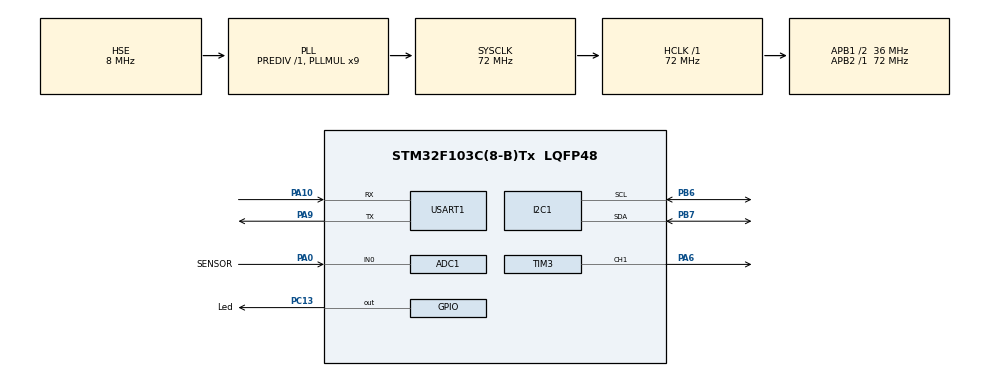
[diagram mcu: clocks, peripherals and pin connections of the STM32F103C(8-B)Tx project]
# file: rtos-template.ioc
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ADC1.Channel-0\#ChannelRegularConversion=ADC_CHANNEL_0
ADC1.ContinuousConvMode=DISABLE
ADC1.DataAlign=ADC_DATAALIGN_RIGHT
ADC1.DiscontinuousConvMode=DISABLE
ADC1.EnableAnalogWatchDog=false
ADC1.EnableRegularConversion=ENABLE
ADC1.ExternalTrigConv=ADC_EXTERNALTRIGCONV_T3_TRGO
ADC1.InjNumberOfConversion=0
ADC1.NbrOfConversion=1
ADC1.NbrOfConversionFlag=1
ADC1.Rank-0\#ChannelRegularConversion=1
ADC1.SamplingTime-0\#ChannelRegularConversion=ADC_SAMPLETIME_1CYCLE_5
ADC1.ScanConvMode=ADC_SCAN_DISABLE
ADC1.master=1
Dma.ADC1.0.Direction=DMA_PERIPH_TO_MEMORY
Dma.ADC1.0.Instance=DMA1_Channel1
Dma.ADC1.0.MemDataAlignment=DMA_MDATAALIGN_HALFWORD
Dma.ADC1.0.MemInc=DMA_MINC_ENABLE
Dma.ADC1.0.Mode=DMA_CIRCULAR
Dma.ADC1.0.PeriphDataAlignment=DMA_PDATAALIGN_HALFWORD
Dma.ADC1.0.PeriphInc=DMA_PINC_DISABLE
Dma.ADC1.0.Priority=DMA_PRIORITY_LOW
Dma.Request0=ADC1
FREERTOS.Tasks01=defaultTask,0,128,StartDefaultTask,Default,NULL
FREERTOS.configTOTAL_HEAP_SIZE=10000
Mcu.Family=STM32F1
Mcu.Name=STM32F103C(8-B)Tx
Mcu.Package=LQFP48
NVIC.DMA1_Channel1_IRQn=true\:5\:0\:false\:false\:true\:true\:false
NVIC.PriorityGroup=NVIC_PRIORITYGROUP_4
NVIC.TIM1_UP_IRQn=true\:0\:0\:false\:false\:true\:false\:false
NVIC.TimeBase=TIM1_UP_IRQn
NVIC.TimeBaseIP=TIM1
PA0-WKUP.GPIO_Label=SENSOR
PA0-WKUP.Signal=ADCx_IN0
PA10.Mode=Asynchronous
PA10.Signal=USART1_RX
PA6.Signal=S_TIM3_CH1
PA9.Mode=Asynchronous
PA9.Signal=USART1_TX
PB6.Mode=I2C
PB6.Signal=I2C1_SCL
PB7.Mode=I2C
PB7.Signal=I2C1_SDA
PC13-TAMPER-RTC.GPIO_Label=Led
PC13-TAMPER-RTC.Signal=GPIO_Output
PD0-OSC_IN.Mode=HSE-External-Oscillator
PD0-OSC_IN.Signal=RCC_OSC_IN
PD1-OSC_OUT.Mode=HSE-External-Oscillator
PD1-OSC_OUT.Signal=RCC_OSC_OUT
ProjectManager.HeapSize=0x200
ProjectManager.StackSize=0x400
ProjectManager.TargetToolchain=Other Toolchains (GPDSC)
RCC.ADCPresc=RCC_ADCPCLK2_DIV6
RCC.AHBFreq_Value=72000000
RCC.APB1CLKDivider=RCC_HCLK_DIV2
RCC.APB1Freq_Value=36000000
RCC.APB1TimFreq_Value=72000000
RCC.APB2Freq_Value=72000000
RCC.APB2TimFreq_Value=72000000
RCC.HCLKFreq_Value=72000000
RCC.PLLMUL=RCC_PLL_MUL9
RCC.PLLSourceVirtual=RCC_PLLSOURCE_HSE
RCC.SYSCLKFreq_VALUE=72000000
RCC.SYSCLKSource=RCC_SYSCLKSOURCE_PLLCLK
RCC.USBFreq_Value=72000000
SH.ADCx_IN0.0=ADC1_IN0,IN0
SH.S_TIM3_CH1.0=TIM3_CH1,Output Compare1 CH1
TIM3.AutoReloadPreload=TIM_AUTORELOAD_PRELOAD_ENABLE
TIM3.Channel-Output\ Compare1\ CH1=TIM_CHANNEL_1
TIM3.Period=56250-1
TIM3.Prescaler=10-1
TIM3.TIM_MasterOutputTrigger=TIM_TRGO_UPDATE
USART1.VirtualMode=VM_ASYNC
VP_FREERTOS_VS_ENABLE.Mode=Enabled
VP_SYS_VS_ND.Mode=No_Debug
VP_SYS_VS_tim1.Mode=TIM1
VP_TIM3_VS_ClockSourceINT.Mode=Internal
board=custom

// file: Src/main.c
/**
  ******************************************************************************
  * @file           : main.c
  * @brief          : Main program body
  ******************************************************************************
  * This notice applies to any and all portions of this file
  * that are not between comment pairs USER CODE BEGIN and
  * USER CODE END. Other portions of this file, whether
  * inserted by the user or by software development tools
  * are owned by their respective copyright owners.
  *
  * Copyright (c) 2020 STMicroelectronics International N.V.
  * All rights reserved.
  *
  * Redistribution and use in source and binary forms, with or without
  * modification, are permitted, provided that the following conditions are met:
  *
  * 1. Redistribution of source code must retain the above copyright notice,
  *    this list of conditions and the following disclaimer.
  * 2. Redistributions in binary form must reproduce the above copyright notice,
  *    this list of conditions and the following disclaimer in the documentation
  *    and/or other materials provided with the distribution.
  * 3. Neither the name of STMicroelectronics nor the names of other
  *    contributors to this software may be used to endorse or promote products
  *    derived from this software without specific written permission.
  * 4. This software, including modifications and/or derivative works of this
  *    software, must execute solely and exclusively on microcontroller or
  *    microprocessor devices manufactured by or for STMicroelectronics.
  * 5. Redistribution and use of this software other than as permitted under
  *    this license is void and will automatically terminate your rights under
  *    this license.
  *
  * THIS SOFTWARE IS PROVIDED BY STMICROELECTRONICS AND CONTRIBUTORS "AS IS"
  * AND ANY EXPRESS, IMPLIED OR STATUTORY WARRANTIES, INCLUDING, BUT NOT
  * LIMITED TO, THE IMPLIED WARRANTIES OF MERCHANTABILITY, FITNESS FOR A
  * PARTICULAR PURPOSE AND NON-INFRINGEMENT OF THIRD PARTY INTELLECTUAL PROPERTY
  * RIGHTS ARE DISCLAIMED TO THE FULLEST EXTENT PERMITTED BY LAW. IN NO EVENT
  * SHALL STMICROELECTRONICS OR CONTRIBUTORS BE LIABLE FOR ANY DIRECT, INDIRECT,
  * INCIDENTAL, SPECIAL, EXEMPLARY, OR CONSEQUENTIAL DAMAGES (INCLUDING, BUT NOT
  * LIMITED TO, PROCUREMENT OF SUBSTITUTE GOODS OR SERVICES; LOSS OF USE, DATA,
  * OR PROFITS; OR BUSINESS INTERRUPTION) HOWEVER CAUSED AND ON ANY THEORY OF
  * LIABILITY, WHETHER IN CONTRACT, STRICT LIABILITY, OR TORT (INCLUDING
  * NEGLIGENCE OR OTHERWISE) ARISING IN ANY WAY OUT OF THE USE OF THIS SOFTWARE,
  * EVEN IF ADVISED OF THE POSSIBILITY OF SUCH DAMAGE.
  *
  ******************************************************************************
  */
#include "main.h"
#include "stm32f1xx_hal.h"
#include "cmsis_os.h"
#include "adc.h"
#include "dma.h"
#include "i2c.h"
#include "tim.h"
#include "usart.h"
#include "gpio.h"

/* USER CODE BEGIN PV */
/* Private variables ---------------------------------------------------------*/

/* USER CODE END PV */

void SystemClock_Config(void);
void MX_FREERTOS_Init(void);

/* USER CODE BEGIN PFP */
/* Private function prototypes -----------------------------------------------*/

/* USER CODE END PFP */

int main(void)
{

  /* MCU Configuration----------------------------------------------------------*/

  /* Reset of all peripherals, Initializes the Flash interface and the Systick. */
  HAL_Init();

  /* Configure the system clock */
  SystemClock_Config();

  /* Initialize all configured peripherals */
  MX_GPIO_Init();
  MX_DMA_Init();
  MX_I2C1_Init();
  MX_USART1_UART_Init();
  MX_ADC1_Init();
  MX_TIM3_Init();

  /* Call init function for freertos objects (in freertos.c) */
  MX_FREERTOS_Init();

  /* Start scheduler */
  osKernelStart();

  /* We should never get here as control is now taken by the scheduler */

  /* Infinite loop */
  /* USER CODE BEGIN WHILE */
  while (1)
  {
    // HAL_GPIO_TogglePin(Led_GPIO_Port,Led_Pin);
    // HAL_Delay(100);
  /* USER CODE END WHILE */

  }

}

void SystemClock_Config(void)
{

  RCC_OscInitTypeDef RCC_OscInitStruct;
  RCC_ClkInitTypeDef RCC_ClkInitStruct;
  RCC_PeriphCLKInitTypeDef PeriphClkInit;

    /**Initializes the CPU, AHB and APB busses clocks
    */
  RCC_OscInitStruct.OscillatorType = RCC_OSCILLATORTYPE_HSE;
  RCC_OscInitStruct.HSEState = RCC_HSE_ON;
  RCC_OscInitStruct.HSEPredivValue = RCC_HSE_PREDIV_DIV1;
  RCC_OscInitStruct.HSIState = RCC_HSI_ON;
  RCC_OscInitStruct.PLL.PLLState = RCC_PLL_ON;
  RCC_OscInitStruct.PLL.PLLSource = RCC_PLLSOURCE_HSE;
  RCC_OscInitStruct.PLL.PLLMUL = RCC_PLL_MUL9;
  if (HAL_RCC_OscConfig(&RCC_OscInitStruct) != HAL_OK)
  {
    _Error_Handler(__FILE__, __LINE__);
  }

    /**Initializes the CPU, AHB and APB busses clocks
    */
  RCC_ClkInitStruct.ClockType = RCC_CLOCKTYPE_HCLK|RCC_CLOCKTYPE_SYSCLK
                              |RCC_CLOCKTYPE_PCLK1|RCC_CLOCKTYPE_PCLK2;
  RCC_ClkInitStruct.SYSCLKSource = RCC_SYSCLKSOURCE_PLLCLK;
  RCC_ClkInitStruct.AHBCLKDivider = RCC_SYSCLK_DIV1;
  RCC_ClkInitStruct.APB1CLKDivider = RCC_HCLK_DIV2;
  RCC_ClkInitStruct.APB2CLKDivider = RCC_HCLK_DIV1;

  if (HAL_RCC_ClockConfig(&RCC_ClkInitStruct, FLASH_LATENCY_2) != HAL_OK)
  {
    _Error_Handler(__FILE__, __LINE__);
  }

  PeriphClkInit.PeriphClockSelection = RCC_PERIPHCLK_ADC;
  PeriphClkInit.AdcClockSelection = RCC_ADCPCLK2_DIV6;
  if (HAL_RCCEx_PeriphCLKConfig(&PeriphClkInit) != HAL_OK)
  {
    _Error_Handler(__FILE__, __LINE__);
  }

    /**Configure the Systick interrupt time
    */
  HAL_SYSTICK_Config(HAL_RCC_GetHCLKFreq()/1000);

    /**Configure the Systick
    */
  HAL_SYSTICK_CLKSourceConfig(SYSTICK_CLKSOURCE_HCLK);

  /* SysTick_IRQn interrupt configuration */
  HAL_NVIC_SetPriority(SysTick_IRQn, 15, 0);
}

void HAL_TIM_PeriodElapsedCallback(TIM_HandleTypeDef *htim)
{
  if (htim->Instance == TIM1) {
    HAL_IncTick();
  }
}

void _Error_Handler(char *file, int line)
{
  while(1)
  {
  }
}

/************************ (C) COPYRIGHT STMicroelectronics *****END OF FILE****/

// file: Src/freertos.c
/* USER CODE BEGIN Header */
/**
  ******************************************************************************
  * File Name          : freertos.c
  * Description        : Code for freertos applications
  ******************************************************************************
  * This notice applies to any and all portions of this file
  * that are not between comment pairs USER CODE BEGIN and
  * USER CODE END. Other portions of this file, whether
  * inserted by the user or by software development tools
  * are owned by their respective copyright owners.
  *
  * Copyright (c) 2020 STMicroelectronics International N.V.
  * All rights reserved.
  *
  * Redistribution and use in source and binary forms, with or without
  * modification, are permitted, provided that the following conditions are met:
  *
  * 1. Redistribution of source code must retain the above copyright notice,
  *    this list of conditions and the following disclaimer.
  * 2. Redistributions in binary form must reproduce the above copyright notice,
  *    this list of conditions and the following disclaimer in the documentation
  *    and/or other materials provided with the distribution.
  * 3. Neither the name of STMicroelectronics nor the names of other
  *    contributors to this software may be used to endorse or promote products
  *    derived from this software without specific written permission.
  * 4. This software, including modifications and/or derivative works of this
  *    software, must execute solely and exclusively on microcontroller or
  *    microprocessor devices manufactured by or for STMicroelectronics.
  * 5. Redistribution and use of this software other than as permitted under
  *    this license is void and will automatically terminate your rights under
  *    this license.
  *
  * THIS SOFTWARE IS PROVIDED BY STMICROELECTRONICS AND CONTRIBUTORS "AS IS"
  * AND ANY EXPRESS, IMPLIED OR STATUTORY WARRANTIES, INCLUDING, BUT NOT
  * LIMITED TO, THE IMPLIED WARRANTIES OF MERCHANTABILITY, FITNESS FOR A
  * PARTICULAR PURPOSE AND NON-INFRINGEMENT OF THIRD PARTY INTELLECTUAL PROPERTY
  * RIGHTS ARE DISCLAIMED TO THE FULLEST EXTENT PERMITTED BY LAW. IN NO EVENT
  * SHALL STMICROELECTRONICS OR CONTRIBUTORS BE LIABLE FOR ANY DIRECT, INDIRECT,
  * INCIDENTAL, SPECIAL, EXEMPLARY, OR CONSEQUENTIAL DAMAGES (INCLUDING, BUT NOT
  * LIMITED TO, PROCUREMENT OF SUBSTITUTE GOODS OR SERVICES; LOSS OF USE, DATA,
  * OR PROFITS; OR BUSINESS INTERRUPTION) HOWEVER CAUSED AND ON ANY THEORY OF
  * LIABILITY, WHETHER IN CONTRACT, STRICT LIABILITY, OR TORT (INCLUDING
  * NEGLIGENCE OR OTHERWISE) ARISING IN ANY WAY OUT OF THE USE OF THIS SOFTWARE,
  * EVEN IF ADVISED OF THE POSSIBILITY OF SUCH DAMAGE.
  *
  ******************************************************************************
  */
/* USER CODE END Header */

#include "FreeRTOS.h"
#include "task.h"
#include "main.h"
#include "cmsis_os.h"

/* USER CODE BEGIN Includes */
#include "usart.h"
#include "gpio.h"
#include "tim.h"
#include "aquisicao.h"
/* USER CODE END Includes */

osThreadId defaultTaskHandle;

void StartDefaultTask(void const * argument);

void MX_FREERTOS_Init(void); /* (MISRA C 2004 rule 8.1) */

void MX_FREERTOS_Init(void) {
  /* USER CODE BEGIN Init */
  aquisicao_inicializar_perifericos();
  /* USER CODE END Init */

  /* USER CODE BEGIN RTOS_SEMAPHORES */
  /* add semaphores, ... */
  aquisicao_inicializar_listas();
  /* USER CODE END RTOS_SEMAPHORES */

  /* Create the thread(s) */
  /* definition and creation of defaultTask */
  osThreadDef(defaultTask, StartDefaultTask, osPriorityNormal, 0, 128);
  defaultTaskHandle = osThreadCreate(osThread(defaultTask), NULL);

  /* USER CODE BEGIN RTOS_THREADS */
  aquisicao_inicializar_tarefas();
  /* USER CODE END RTOS_THREADS */

}

void StartDefaultTask(void const * argument)
{

  /* USER CODE BEGIN StartDefaultTask */
  /* Infinite loop */

  for (;;)
  {
    HAL_GPIO_TogglePin(Led_GPIO_Port, Led_Pin);
    osDelay(500);
  }
  /* USER CODE END StartDefaultTask */
}

/************************ (C) COPYRIGHT STMicroelectronics *****END OF FILE****/
